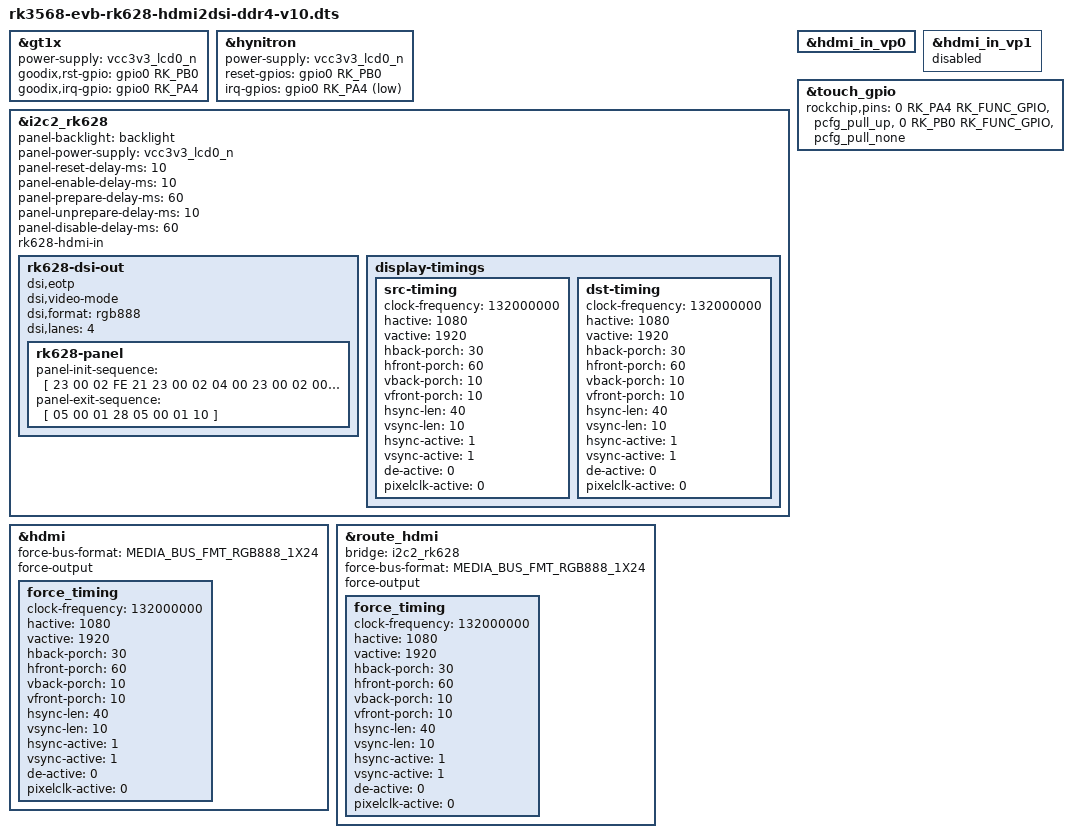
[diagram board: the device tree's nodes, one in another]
// SPDX-License-Identifier: (GPL-2.0+ OR MIT)
/*
 * Copyright (c) 2020 Rockchip Electronics Co., Ltd.
 *
 */

#include "rk3568-evb-rk628-ddr4-v10.dtsi"
#include "rk3568-android.dtsi"
#include <dt-bindings/display/media-bus-format.h>

&gt1x {
	status = "okay";
	power-supply = <&vcc3v3_lcd0_n>;
	goodix,rst-gpio = <&gpio0 RK_PB0 GPIO_ACTIVE_HIGH>;
	goodix,irq-gpio = <&gpio0 RK_PA4 IRQ_TYPE_LEVEL_LOW>;
};

&hynitron {
	status = "okay";
	power-supply = <&vcc3v3_lcd0_n>;
	reset-gpios = <&gpio0 RK_PB0 GPIO_ACTIVE_HIGH>;
	irq-gpios = <&gpio0 RK_PA4 GPIO_ACTIVE_LOW>;
};

&i2c2_rk628 {
	panel-backlight = <&backlight>;
	panel-power-supply = <&vcc3v3_lcd0_n>;
	panel-reset-delay-ms = <10>;
	panel-enable-delay-ms = <10>;
	panel-prepare-delay-ms = <60>;
	panel-unprepare-delay-ms = <10>;
	panel-disable-delay-ms = <60>;

	rk628-hdmi-in;
	rk628-dsi-out {
		//rockchip,dual-channel;
		dsi,eotp;
		dsi,video-mode;
		dsi,format = "rgb888";
		dsi,lanes  = <4>;
		status = "okay";

		rk628-panel {
			panel-init-sequence = [
				23 00 02 FE 21
				23 00 02 04 00
				23 00 02 00 64
				23 00 02 2A 00
				23 00 02 26 64
				23 00 02 54 00
				23 00 02 50 64
				23 00 02 7B 00
				23 00 02 77 64
				23 00 02 A2 00
				23 00 02 9D 64
				23 00 02 C9 00
				23 00 02 C5 64
				23 00 02 01 71
				23 00 02 27 71
				23 00 02 51 71
				23 00 02 78 71
				23 00 02 9E 71
				23 00 02 C6 71
				23 00 02 02 89
				23 00 02 28 89
				23 00 02 52 89
				23 00 02 79 89
				23 00 02 9F 89
				23 00 02 C7 89
				23 00 02 03 9E
				23 00 02 29 9E
				23 00 02 53 9E
				23 00 02 7A 9E
				23 00 02 A0 9E
				23 00 02 C8 9E
				23 00 02 09 00
				23 00 02 05 B0
				23 00 02 31 00
				23 00 02 2B B0
				23 00 02 5A 00
				23 00 02 55 B0
				23 00 02 80 00
				23 00 02 7C B0
				23 00 02 A7 00
				23 00 02 A3 B0
				23 00 02 CE 00
				23 00 02 CA B0
				23 00 02 06 C0
				23 00 02 2D C0
				23 00 02 56 C0
				23 00 02 7D C0
				23 00 02 A4 C0
				23 00 02 CB C0
				23 00 02 07 CF
				23 00 02 2F CF
				23 00 02 58 CF
				23 00 02 7E CF
				23 00 02 A5 CF
				23 00 02 CC CF
				23 00 02 08 DD
				23 00 02 30 DD
				23 00 02 59 DD
				23 00 02 7F DD
				23 00 02 A6 DD
				23 00 02 CD DD
				23 00 02 0E 15
				23 00 02 0A E9
				23 00 02 36 15
				23 00 02 32 E9
				23 00 02 5F 15
				23 00 02 5B E9
				23 00 02 85 15
				23 00 02 81 E9
				23 00 02 AD 15
				23 00 02 A9 E9
				23 00 02 D3 15
				23 00 02 CF E9
				23 00 02 0B 14
				23 00 02 33 14
				23 00 02 5C 14
				23 00 02 82 14
				23 00 02 AA 14
				23 00 02 D0 14
				23 00 02 0C 36
				23 00 02 34 36
				23 00 02 5D 36
				23 00 02 83 36
				23 00 02 AB 36
				23 00 02 D1 36
				23 00 02 0D 6B
				23 00 02 35 6B
				23 00 02 5E 6B
				23 00 02 84 6B
				23 00 02 AC 6B
				23 00 02 D2 6B
				23 00 02 13 5A
				23 00 02 0F 94
				23 00 02 3B 5A
				23 00 02 37 94
				23 00 02 64 5A
				23 00 02 60 94
				23 00 02 8A 5A
				23 00 02 86 94
				23 00 02 B2 5A
				23 00 02 AE 94
				23 00 02 D8 5A
				23 00 02 D4 94
				23 00 02 10 D1
				23 00 02 38 D1
				23 00 02 61 D1
				23 00 02 87 D1
				23 00 02 AF D1
				23 00 02 D5 D1
				23 00 02 11 04
				23 00 02 39 04
				23 00 02 62 04
				23 00 02 88 04
				23 00 02 B0 04
				23 00 02 D6 04
				23 00 02 12 05
				23 00 02 3A 05
				23 00 02 63 05
				23 00 02 89 05
				23 00 02 B1 05
				23 00 02 D7 05
				23 00 02 18 AA
				23 00 02 14 36
				23 00 02 42 AA
				23 00 02 3D 36
				23 00 02 69 AA
				23 00 02 65 36
				23 00 02 8F AA
				23 00 02 8B 36
				23 00 02 B7 AA
				23 00 02 B3 36
				23 00 02 DD AA
				23 00 02 D9 36
				23 00 02 15 74
				23 00 02 3F 74
				23 00 02 66 74
				23 00 02 8C 74
				23 00 02 B4 74
				23 00 02 DA 74
				23 00 02 16 9F
				23 00 02 40 9F
				23 00 02 67 9F
				23 00 02 8D 9F
				23 00 02 B5 9F
				23 00 02 DB 9F
				23 00 02 17 DC
				23 00 02 41 DC
				23 00 02 68 DC
				23 00 02 8E DC
				23 00 02 B6 DC
				23 00 02 DC DC
				23 00 02 1D FF
				23 00 02 19 03
				23 00 02 47 FF
				23 00 02 43 03
				23 00 02 6E FF
				23 00 02 6A 03
				23 00 02 94 FF
				23 00 02 90 03
				23 00 02 BC FF
				23 00 02 B8 03
				23 00 02 E2 FF
				23 00 02 DE 03
				23 00 02 1A 35
				23 00 02 44 35
				23 00 02 6B 35
				23 00 02 91 35
				23 00 02 B9 35
				23 00 02 DF 35
				23 00 02 1B 45
				23 00 02 45 45
				23 00 02 6C 45
				23 00 02 92 45
				23 00 02 BA 45
				23 00 02 E0 45
				23 00 02 1C 55
				23 00 02 46 55
				23 00 02 6D 55
				23 00 02 93 55
				23 00 02 BB 55
				23 00 02 E1 55
				23 00 02 22 FF
				23 00 02 1E 68
				23 00 02 4C FF
				23 00 02 48 68
				23 00 02 73 FF
				23 00 02 6F 68
				23 00 02 99 FF
				23 00 02 95 68
				23 00 02 C1 FF
				23 00 02 BD 68
				23 00 02 E7 FF
				23 00 02 E3 68
				23 00 02 1F 7E
				23 00 02 49 7E
				23 00 02 70 7E
				23 00 02 96 7E
				23 00 02 BE 7E
				23 00 02 E4 7E
				23 00 02 20 97
				23 00 02 4A 97
				23 00 02 71 97
				23 00 02 97 97
				23 00 02 BF 97
				23 00 02 E5 97
				23 00 02 21 B5
				23 00 02 4B B5
				23 00 02 72 B5
				23 00 02 98 B5
				23 00 02 C0 B5
				23 00 02 E6 B5
				23 00 02 25 F0
				23 00 02 23 E8
				23 00 02 4F F0
				23 00 02 4D E8
				23 00 02 76 F0
				23 00 02 74 E8
				23 00 02 9C F0
				23 00 02 9A E8
				23 00 02 C4 F0
				23 00 02 C2 E8
				23 00 02 EA F0
				23 00 02 E8 E8
				23 00 02 24 FF
				23 00 02 4E FF
				23 00 02 75 FF
				23 00 02 9B FF
				23 00 02 C3 FF
				23 00 02 E9 FF
				23 00 02 FE 3D
				23 00 02 00 04
				23 00 02 FE 23
				23 00 02 08 82
				23 00 02 0A 00
				23 00 02 0B 00
				23 00 02 0C 01
				23 00 02 16 00
				23 00 02 18 02
				23 00 02 1B 04
				23 00 02 19 04
				23 00 02 1C 81
				23 00 02 1F 00
				23 00 02 20 03
				23 00 02 23 04
				23 00 02 21 01
				23 00 02 54 63
				23 00 02 55 54
				23 00 02 6E 45
				23 00 02 6D 36
				23 00 02 FE 3D
				23 00 02 55 78
				23 00 02 FE 20
				23 00 02 26 30
				23 00 02 FE 3D
				23 00 02 20 71
				23 00 02 50 8F
				23 00 02 51 8F
				23 00 02 FE 00
				23 00 02 35 00
				05 78 01 11
				05 00 01 29
			];

			panel-exit-sequence = [
				05 00 01 28
				05 00 01 10
			];
		};
	};

	display-timings {
		src-timing {
			clock-frequency = <132000000>;
			hactive = <1080>;
			vactive = <1920>;
			hback-porch = <30>;
			hfront-porch = <60>;
			vback-porch = <10>;
			vfront-porch = <10>;
			hsync-len = <40>;
			vsync-len = <10>;
			hsync-active = <1>;
			vsync-active = <1>;
			de-active = <0>;
			pixelclk-active = <0>;
		};

		dst-timing {
			clock-frequency = <132000000>;
			hactive = <1080>;
			vactive = <1920>;
			hback-porch = <30>;
			hfront-porch = <60>;
			vback-porch = <10>;
			vfront-porch = <10>;
			hsync-len = <40>;
			vsync-len = <10>;
			hsync-active = <1>;
			vsync-active = <1>;
			de-active = <0>;
			pixelclk-active = <0>;
		};
	};
};

&hdmi {
	status = "okay";
	force-bus-format = <MEDIA_BUS_FMT_RGB888_1X24>;
	force-output;
	force_timing{
		clock-frequency = <132000000>;
		hactive = <1080>;
		vactive = <1920>;
		hback-porch = <30>;
		hfront-porch = <60>;
		vback-porch = <10>;
		vfront-porch = <10>;
		hsync-len = <40>;
		vsync-len = <10>;
		hsync-active = <1>;
		vsync-active = <1>;
		de-active = <0>;
		pixelclk-active = <0>;
	};
};

&hdmi_in_vp0 {
	status = "okay";
};

&hdmi_in_vp1 {
	status = "disabled";
};

&route_hdmi {
	status = "okay";

	bridge = <&i2c2_rk628>;
	force-bus-format = <MEDIA_BUS_FMT_RGB888_1X24>;
	force-output;
	force_timing{
		clock-frequency = <132000000>;
		hactive = <1080>;
		vactive = <1920>;
		hback-porch = <30>;
		hfront-porch = <60>;
		vback-porch = <10>;
		vfront-porch = <10>;
		hsync-len = <40>;
		vsync-len = <10>;
		hsync-active = <1>;
		vsync-active = <1>;
		de-active = <0>;
		pixelclk-active = <0>;
	};
};

&touch_gpio {
	rockchip,pins = <0 RK_PA4 RK_FUNC_GPIO &pcfg_pull_up>,
			<0 RK_PB0 RK_FUNC_GPIO &pcfg_pull_none>;
};
